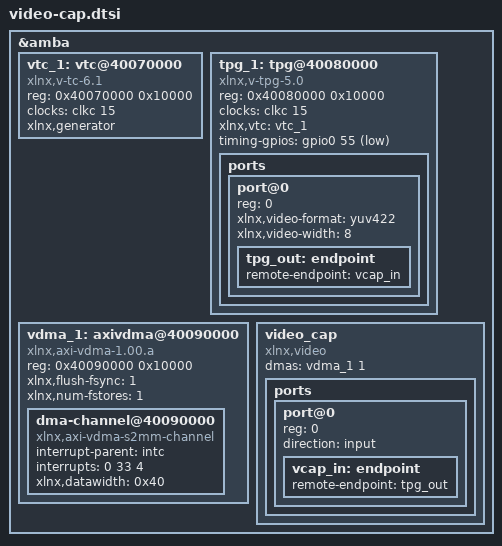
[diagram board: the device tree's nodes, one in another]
/*
 *  Copyright (C) 2011 - 2014 Xilinx
 *
 * This software is licensed under the terms of the GNU General Public
 * License version 2, as published by the Free Software Foundation, and
 * may be copied, distributed, and modified under those terms.
 *
 * This program is distributed in the hope that it will be useful,
 * but WITHOUT ANY WARRANTY; without even the implied warranty of
 * MERCHANTABILITY or FITNESS FOR A PARTICULAR PURPOSE.  See the
 * GNU General Public License for more details.
 */

&amba {
	vtc_1: vtc@40070000 {
		compatible = "xlnx,v-tc-6.1";
		reg = <0x40070000 0x10000>;
		clocks = <&clkc 15>;
		xlnx,generator;
	};

	tpg_1: tpg@40080000 {
		compatible = "xlnx,v-tpg-5.0";
		reg = <0x40080000 0x10000>;
		clocks = <&clkc 15>;

		xlnx,vtc = <&vtc_1>;
		timing-gpios = <&gpio0 55 1>;

		ports {
			#address-cells = <1>;
			#size-cells = <0>;

			port@0 {
				reg = <0>;

				xlnx,video-format = "yuv422";
				xlnx,video-width = <8>;

				tpg_out: endpoint {
					remote-endpoint = <&vcap_in>;
				};
			};
		};
	};

	vdma_1: axivdma@40090000 {
		compatible = "xlnx,axi-vdma-1.00.a";
		reg = <0x40090000 0x10000>;

		xlnx,flush-fsync = <1>;
		xlnx,num-fstores = <1>;

		#dma-cells = <1>;
		dma-channel@40090000 {
			compatible = "xlnx,axi-vdma-s2mm-channel";
			interrupt-parent = <&intc>;
			interrupts = <0 33 4>;
			xlnx,datawidth = <0x40>;
		};
	};

	video_cap {
		compatible = "xlnx,video";
		dmas = <&vdma_1 1>;
		dma-names = "port0";

		ports {
			#address-cells = <1>;
			#size-cells = <0>;

			port@0 {
				reg = <0>;
				direction = "input";
				vcap_in: endpoint {
					remote-endpoint = <&tpg_out>;
				};
			};
		};
	};
};
